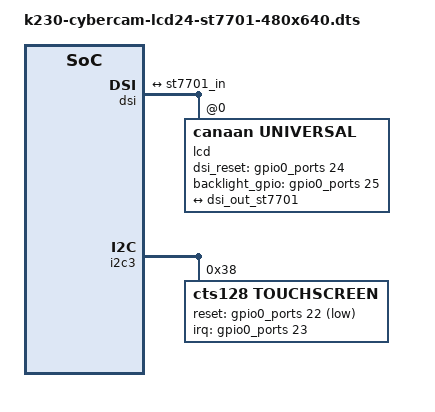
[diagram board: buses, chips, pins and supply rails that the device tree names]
/dts-v1/;
/plugin/;

/ {
	fragment@0 {
		target = <&dsi>;
		__overlay__ {
			#address-cells = <1>;
			#size-cells = <0>;
			ports {
				#address-cells = <1>;
				#size-cells = <0>;
				port@1 {
					reg = <1>;
					dsi_out_st7701: endpoint {
						remote-endpoint = <&st7701_in>;
					};
				};
			};
			
			lcd: panel@0 {
				dsi_reset-gpios = <&gpio0_ports 24 0>;//GPIO_ACTIVE_HIGH
				backlight_gpio-gpios = <&gpio0_ports 25 0>;//GPIO_ACTIVE_HIGH
				
				compatible = "canaan,universal";
				reg = <0>;
				
				panel-width-mm = <480>;
				panel-height-mm = <640>;
				panel-dsi-lane = <2>;
				
				panel-init-sequence = [
				39 00 06 ff 77 01 00 00 13
				39 00 02 ef 08
				39 00 06 ff 77 01 00 00 10
				39 00 03 c0 4f 00
				39 00 03 c1 10 0c
				39 00 03 c2 31 14
				39 00 02 cc 10
				
				39 00 11 b0 00 0b 13 0d 10 07 02 08 07 1f 04 11 0f 28 2f 1f
				39 00 11 b1 00 0c 13 0c 10 05 02 08 08 1e 05 13 11 27 30 1f
				
				39 00 06 ff 77 01 00 00 11
				
				39 00 02 b0 5d
				39 00 02 b1 5d
				39 00 02 b2 87
				39 00 02 b3 80
				39 00 02 b5 45
				39 00 02 b7 85
				39 00 02 b8 20
				39 00 02 c0 09
				39 00 02 c1 78
				39 00 02 c2 78
				39 00 02 d0 88
				
				39 00 04 e0 00 00 02
				39 00 0c e1 04 b0 06 b0 05 b0 07 b0 00 44 44
				39 00 0d e2 20 20 44 44 96 a0 00 00 96 a0 00 00
				39 00 05 e3 00 00 22 22
				39 00 03 e4 44 44
				39 00 11 e5 0c 90 b0 a0 0e 92 b0 a0 08 8c b0 a0 0a 8e b0 a0
				39 00 05 e6 00 00 22 22
				39 00 03 e7 44 44
				39 00 11 e8 0d 91 b0 a0 0f 93 b0 a0 09 8d b0 a0 0b 8f b0 a0
				
				39 00 03 e9 36 00
				
				39 00 08 eb 00 00 e4 e4 44 88 40
				39 00 11 ed c1 a2 bf 0f 67 45 ff ff ff ff 54 76 f0 fb 2a 1c
				39 00 07 ef 10 0d 04 08 3f 1f
				
				39 00 06 ff 77 01 00 00 13
				39 00 03 e8 00 0e
				39 00 06 ff 77 01 00 00 00
				39 ff 01 11
				39 00 06 ff 77 01 00 00 13
				39 ff 03 e8 00 0c
				39 00 03 e8 00 00
				39 00 06 ff 77 01 00 00 00
				39 00 02 3a 70
				39 ff 01 29
				];
				
				display-timings {
					timing-0 {
						clock-frequency = <25000000>;
						hactive = <480>;
						vactive = <640>;
						hfront-porch = <200>;
						hback-porch = <10>;
						hsync-len = <6>;
						vfront-porch = <20>;
						vback-porch = <20>;
						vsync-len = <60>;
						
					};
				};
				
				
				ports {
					#address-cells = <1>;
					#size-cells = <0>;
					
					port@0 {
						reg = <0>;
						st7701_in: endpoint {
							remote-endpoint = <&dsi_out_st7701>;
						};
					};
				};
			};
			
		};
	};
	fragment@1 {
		target = <&vo>;
		__overlay__ {
			vth_line = <10>;
		};
	};
	fragment@2 {
		target = <&i2c3>;
		__overlay__ {
			#address-cells = <1>;
			#size-cells = <0>;
			status = "okay";
			touchscreen@38{
				compatible = "cts128,touchscreen";
				reg = <0x38>;
				reset-gpios = <&gpio0_ports 22 1>;//GPIO_ACTIVE_LOW
				interrupt-parent = <&gpio0_ports>;
				interrupts = <23 2>;//IRQ_TYPE_EDGE_RISING	1 or IRQ_TYPE_EDGE_FALLING	2
				cts128,max-x = <480>;
				cts128,max-y = <640>;
				cts128,x-flip = <1>;
				cts128,y-flip = <0>;
				status = "okay";
			};
		};
	};
};

